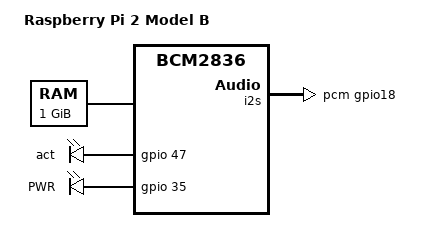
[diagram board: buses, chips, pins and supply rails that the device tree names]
/dts-v1/;
#include "bcm2836.dtsi"
#include "bcm2835-rpi.dtsi"

/ {
	compatible = "raspberrypi,2-model-b", "brcm,bcm2836";
	model = "Raspberry Pi 2 Model B";

	memory {
		reg = <0 0x40000000>;
	};

	leds {
		act {
			gpios = <&gpio 47 0>;
		};

		pwr {
			label = "PWR";
			gpios = <&gpio 35 0>;
			default-state = "keep";
			linux,default-trigger = "default-on";
		};
	};
};

&i2s {
	pinctrl-names = "default";
	pinctrl-0 = <&pcm_gpio18>;
};
